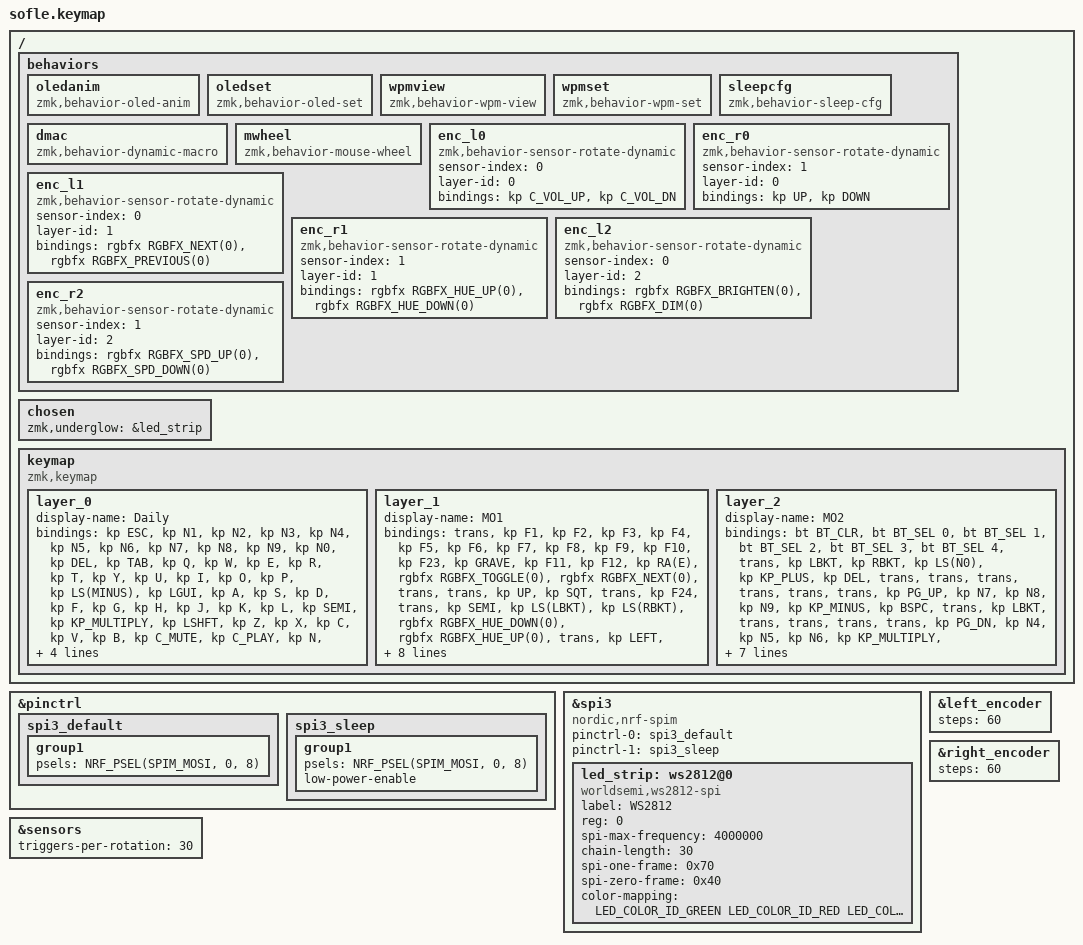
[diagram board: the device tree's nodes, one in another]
/*
 * Copyright (c) 2020 The ZMK Contributors
 *
 * SPDX-License-Identifier: MIT
 */

#include <behaviors.dtsi>
#include <dt-bindings/zmk/keys.h>
#include <dt-bindings/zmk/bt.h>
#include <dt-bindings/zmk/ext_power.h>
#include <dt-bindings/zmk/rgb_fx.h>
#include <dt-bindings/zmk/outputs.h>
/* Mouse input from keyboard (&mmv/&mkp/&msc). Comes built in to ZMK with
   CONFIG_ZMK_POINTING, which is already active for the encoder wheel. */
#include <dt-bindings/zmk/pointing.h>

/ {
    behaviors {
        // Cycles the right OLED animation (gem/cat/head/spaceman)
        oledanim: oledanim {
            compatible = "zmk,behavior-oled-anim";
            #binding-cells = <0>;
        };

        // Internal central->peripheral relay: sets the animation by
        // index. Not bound to any key; the ZMK Studio RPC handler calls
        // it, the same way the RGB uses &rgbsync. Without it the web
        // changed the animation only on the central half, which is not
        // the one with the animated screen, so nothing happened.
        oledset: oledset {
            compatible = "zmk,behavior-oled-set";
            #binding-cells = <1>;
        };

        // WPM view on the LEFT screen (bongo cat, luna, number,
        // speedometer, graph). &wpmview cycles; &wpmset picks one by
        // index and is what the ZMK Studio RPC uses.
        wpmview: wpmview {
            compatible = "zmk,behavior-wpm-view";
            #binding-cells = <0>;
        };

        wpmset: wpmset {
            compatible = "zmk,behavior-wpm-set";
            #binding-cells = <1>;
        };

        // Internal central->peripheral relay for the deep sleep setting
        // (enabled + minutes). Like &oledset, not bound to any key: the
        // RPC handler invokes it. Needed because each half watches its
        // own inactivity, so the setting has to reach both or the
        // peripheral keeps the old delay.
        sleepcfg: sleepcfg {
            compatible = "zmk,behavior-sleep-cfg";
            #binding-cells = <2>;
        };

        // Hot-editable macros (CODEKEEB PATCH; see
        // src/behaviors/behavior_dynamic_macro.c). &dmac N replays slot N,
        // whose content is written to keyboard flash from the web editor.
        dmac: dmac {
            compatible = "zmk,behavior-dynamic-macro";
            #binding-cells = <1>;
        };

        // Discrete mouse wheel (CODEKEEB PATCH; see
        // src/behaviors/behavior_mouse_wheel.c). One HID wheel tick per
        // press: &mwheel 0 = up, 1 = down, 2 = left, 3 = right. Unlike
        // ZMK's stock &msc this works when fired from an encoder.
        mwheel: mwheel {
            compatible = "zmk,behavior-mouse-wheel";
            #binding-cells = <1>;
        };

        // Encoder rotation bindings are editable live from ZMK Studio.
        // sensor-index: 0 = left encoder, 1 = right encoder.
        // layer-id: 0 = Daily, 1 = MO1, 2 = MO2.
        enc_l0: enc_l0 {
            compatible = "zmk,behavior-sensor-rotate-dynamic";
            #sensor-binding-cells = <0>;
            sensor-index = <0>;
            layer-id = <0>;
            bindings = <&kp C_VOL_UP>, <&kp C_VOL_DN>;
        };
        enc_r0: enc_r0 {
            compatible = "zmk,behavior-sensor-rotate-dynamic";
            #sensor-binding-cells = <0>;
            sensor-index = <1>;
            layer-id = <0>;
            bindings = <&kp UP>, <&kp DOWN>;
        };
        enc_l1: enc_l1 {
            compatible = "zmk,behavior-sensor-rotate-dynamic";
            #sensor-binding-cells = <0>;
            sensor-index = <0>;
            layer-id = <1>;
            bindings = <&rgbfx RGBFX_NEXT(0)>, <&rgbfx RGBFX_PREVIOUS(0)>;
        };
        enc_r1: enc_r1 {
            compatible = "zmk,behavior-sensor-rotate-dynamic";
            #sensor-binding-cells = <0>;
            sensor-index = <1>;
            layer-id = <1>;
            bindings = <&rgbfx RGBFX_HUE_UP(0)>, <&rgbfx RGBFX_HUE_DOWN(0)>;
        };
        enc_l2: enc_l2 {
            compatible = "zmk,behavior-sensor-rotate-dynamic";
            #sensor-binding-cells = <0>;
            sensor-index = <0>;
            layer-id = <2>;
            bindings = <&rgbfx RGBFX_BRIGHTEN(0)>, <&rgbfx RGBFX_DIM(0)>;
        };
        enc_r2: enc_r2 {
            compatible = "zmk,behavior-sensor-rotate-dynamic";
            #sensor-binding-cells = <0>;
            sensor-index = <1>;
            layer-id = <2>;
            bindings = <&rgbfx RGBFX_SPD_UP(0)>, <&rgbfx RGBFX_SPD_DOWN(0)>;
        };
    };
};

/* IMPORTANT - DO NOT DELETE THIS BLOCK EVEN IF IT LOOKS "DUPLICATE":
 * ZMK's sofle shield (>= v0.3) ships its own
 * boards/nice_nano_v2.overlay with MOSI on P0.06 and chain 36, applied
 * AFTER config/boards/nice_nano_v2.overlay, overriding it. The keymap is
 * the last thing to enter the devicetree, so only from here can we
 * enforce this variant's real pin (P0.08) and the 30-LED chain.
 * (It happened once: deleted as "redundant" and the LEDs died for
 * a full day of debugging. Verified by reading SPIM3's PSEL.MOSI
 * live over USB logging.) */

#include <dt-bindings/led/led.h>

&pinctrl {
    spi3_default: spi3_default {
        group1 {
            psels = <NRF_PSEL(SPIM_MOSI, 0, 8)>;
        };
    };

    spi3_sleep: spi3_sleep {
        group1 {
            psels = <NRF_PSEL(SPIM_MOSI, 0, 8)>;
            low-power-enable;
        };
    };
};

&spi3 {
    compatible = "nordic,nrf-spim";
    status = "okay";
    pinctrl-0 = <&spi3_default>;
    pinctrl-1 = <&spi3_sleep>;
    pinctrl-names = "default", "sleep";

    led_strip: ws2812@0 {
        compatible = "worldsemi,ws2812-spi";
        label = "WS2812";
        reg = <0>;
        spi-max-frequency = <4000000>;
        chain-length = <30>;
        spi-one-frame = <0x70>;
        spi-zero-frame = <0x40>;
        color-mapping = <LED_COLOR_ID_GREEN LED_COLOR_ID_RED LED_COLOR_ID_BLUE>;
    };
};

/ {
    chosen {
        zmk,underglow = &led_strip;
    };
};

/ {
    keymap {
        compatible = "zmk,keymap";

        layer_0 {
            display-name = "Daily";
            bindings = <
                /* row 0: positions 0-5 left / 6-11 right */
                &kp ESC &kp N1 &kp N2 &kp N3 &kp N4 &kp N5 &kp N6 &kp N7 &kp N8 &kp N9 &kp N0 &kp DEL
                /* row 1: positions 12-17 / 18-23 */
                &kp TAB &kp Q &kp W &kp E &kp R &kp T &kp Y &kp U &kp I &kp O &kp P &kp LS(MINUS)
                /* row 2: positions 24-29 / 30-35 */
                &kp LGUI &kp A &kp S &kp D &kp F &kp G &kp H &kp J &kp K &kp L &kp SEMI &kp KP_MULTIPLY
                /* row 3: positions 36-42 left / 43-49 right */
                &kp LSHFT &kp Z &kp X &kp C &kp V &kp B &kp C_MUTE &kp C_PLAY &kp N &kp M &kp COMMA &kp DOT &kp FSLH &kp PSCRN
                /* thumbs: positions 50-54 left / 55-59 right */
                &kp CAPS &kp LALT &mo 1 &kp LCTRL &kp SPACE &kp RET &kp BSPC &mo 2 &kp RALT &kp RSHFT
            >;
            sensor-bindings = <&enc_l0 &enc_r0>;
        };

        layer_1 {
            display-name = "MO1";
            bindings = <
                /* row 0 */
                &trans &kp F1 &kp F2 &kp F3 &kp F4 &kp F5 &kp F6 &kp F7 &kp F8 &kp F9 &kp F10 &kp F23
                /* row 1 */
                &kp GRAVE &kp F11 &kp F12 &kp RA(E) &rgbfx RGBFX_TOGGLE(0) &rgbfx RGBFX_NEXT(0) &trans &trans &kp UP &kp SQT &trans &kp F24
                /* row 2 */
                &trans &kp SEMI &kp LS(LBKT) &kp LS(RBKT) &rgbfx RGBFX_HUE_DOWN(0) &rgbfx RGBFX_HUE_UP(0) &trans &kp LEFT &kp DOWN &kp RIGHT &trans &kp HOME
                /* row 3 */
                &trans &studio_unlock &trans &trans &rgbfx RGBFX_DIM(0) &rgbfx RGBFX_BRIGHTEN(0) &wpmview &oledanim &trans &trans &trans &trans &kp BSLH &kp END
                /* thumbs */
                &trans &trans &trans &trans &trans &trans &trans &trans &trans &trans
            >;
            sensor-bindings = <&enc_l1 &enc_r1>;
        };

        layer_2 {
            display-name = "MO2";
            bindings = <
                /* row 0 */
                &bt BT_CLR &bt BT_SEL 0 &bt BT_SEL 1 &bt BT_SEL 2 &bt BT_SEL 3 &bt BT_SEL 4 &trans &kp LBKT &kp RBKT &kp LS(N0) &kp KP_PLUS &kp DEL
                /* row 1 */
                &trans &trans &trans &trans &trans &trans &kp PG_UP &kp N7 &kp N8 &kp N9 &kp KP_MINUS &kp BSPC
                /* row 2 */
                &trans &kp LBKT &trans &trans &trans &trans &kp PG_DN &kp N4 &kp N5 &kp N6 &kp KP_MULTIPLY &kp KP_MULTIPLY
                /* row 3 */
                &trans &kp K_UNDO &kp K_CUT &kp K_COPY &kp K_PASTE &trans &trans &rgbfx RGBFX_TOGGLE(0) &kp N0 &kp N1 &kp N2 &kp N3 &kp KP_SLASH &kp COMMA
                /* thumbs */
                &trans &trans &trans &trans &trans &trans &trans &trans &kp RALT &trans
            >;
            sensor-bindings = <&enc_l2 &enc_r2>;
        };
    };
};

/* CODEKEEB PATCH: one rotation event per physical detent (2 quadrature
 * transitions per detent on this hardware). */
&left_encoder {
    steps = <60>;
};

&right_encoder {
    steps = <60>;
};

&sensors {
    triggers-per-rotation = <30>;
};
